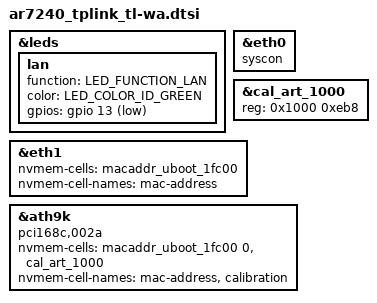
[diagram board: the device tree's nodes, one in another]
// SPDX-License-Identifier: GPL-2.0-or-later OR MIT

#include <dt-bindings/leds/common.h>

#include "ar7240_tplink.dtsi"

&leds {
	lan {
		function = LED_FUNCTION_LAN;
		color = <LED_COLOR_ID_GREEN>;
		gpios = <&gpio 13 GPIO_ACTIVE_LOW>;
	};
};

&eth0 {
	compatible = "syscon", "simple-mfd";
};

&cal_art_1000 {
	reg = <0x1000 0xeb8>;
};

&eth1 {
	nvmem-cells = <&macaddr_uboot_1fc00>;
	nvmem-cell-names = "mac-address";
};

&ath9k {
	compatible = "pci168c,002a";
	nvmem-cells = <&macaddr_uboot_1fc00 0>, <&cal_art_1000>;
	nvmem-cell-names = "mac-address", "calibration";
};
